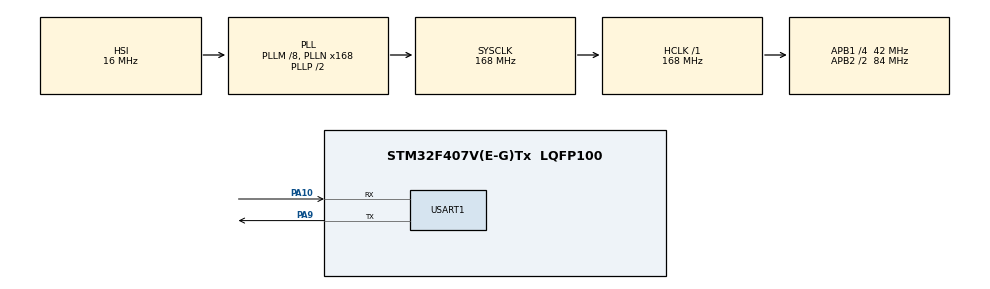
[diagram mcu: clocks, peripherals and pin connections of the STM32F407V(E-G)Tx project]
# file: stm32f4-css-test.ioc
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Mcu.Family=STM32F4
PH0-OSC_IN.Signal=RCC_OSC_IN
RCC.CortexFreq_Value=168000000
PA10.Mode=Asynchronous
RCC.APB1CLKDivider=RCC_HCLK_DIV4
RCC.SYSCLKSource=RCC_SYSCLKSOURCE_PLLCLK
ProjectManager.StackSize=0x400
PA13.Signal=SYS_JTMS-SWDIO
PA9.Mode=Asynchronous
ProjectManager.TargetToolchain=STM32CubeIDE
RCC.HCLKFreq_Value=168000000
RCC.APB2TimFreq_Value=168000000
PA9.Signal=USART1_TX
RCC.LSE_VALUE=32768
RCC.AHBFreq_Value=168000000
PH0-OSC_IN.Mode=HSE-External-Oscillator
RCC.HSE_VALUE=8000000
board=custom
RCC.VCOOutputFreq_Value=336000000
RCC.APB2Freq_Value=84000000
PA14.Mode=Serial_Wire
PH1-OSC_OUT.Signal=RCC_OSC_OUT
PA13.Mode=Serial_Wire
Mcu.Name=STM32F407V(E-G)Tx
PH1-OSC_OUT.Mode=HSE-External-Oscillator
RCC.48MHZClocksFreq_Value=84000000
RCC.SYSCLKFreq_VALUE=168000000
Mcu.Package=LQFP100
USART1.VirtualMode=VM_ASYNC
PA10.Signal=USART1_RX
PA14.Signal=SYS_JTCK-SWCLK
ProjectManager.HeapSize=0x200
RCC.HSI_VALUE=16000000
NVIC.PriorityGroup=NVIC_PRIORITYGROUP_4
RCC.APB2CLKDivider=RCC_HCLK_DIV2
RCC.PLLM=8
RCC.PLLN=168
RCC.APB1TimFreq_Value=84000000
RCC.APB1Freq_Value=42000000

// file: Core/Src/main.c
/* USER CODE BEGIN Header */
/**
  ******************************************************************************
  * @file           : main.c
  * @brief          : Main program body
  ******************************************************************************
  * @attention
  *
  * <h2><center>&copy; Copyright (c) 2021 STMicroelectronics.
  * All rights reserved.</center></h2>
  *
  * This software component is licensed by ST under BSD 3-Clause license,
  * the "License"; You may not use this file except in compliance with the
  * License. You may obtain a copy of the License at:
  *                        opensource.org/licenses/BSD-3-Clause
  *
  ******************************************************************************
  */
/* USER CODE END Header */
#include "main.h"

UART_HandleTypeDef huart1;

void SystemClock_Config(void);
static void MX_GPIO_Init(void);
static void MX_USART1_UART_Init(void);
/* USER CODE BEGIN PFP */
int clock_control__high_clocks_startup(void);
int app_main(void);
/* USER CODE END PFP */

int main(void)
{

  /* MCU Configuration--------------------------------------------------------*/

  /* Reset of all peripherals, Initializes the Flash interface and the Systick. */
  HAL_Init();

  /* USER CODE BEGIN Init */
#if 0
  /* USER CODE END Init */

  /* Configure the system clock */
  SystemClock_Config();

  /* USER CODE BEGIN SysInit */
#endif
  clock_control__high_clocks_startup();
  /* USER CODE END SysInit */

  /* Initialize all configured peripherals */
  MX_GPIO_Init();
  MX_USART1_UART_Init();
  /* USER CODE BEGIN 2 */
  app_main();
  /* USER CODE END 2 */

  /* Infinite loop */
  /* USER CODE BEGIN WHILE */
  while (1)
  {
    break;
    /* USER CODE END WHILE */

  }
}

void SystemClock_Config(void)
{
  RCC_OscInitTypeDef RCC_OscInitStruct = {0};
  RCC_ClkInitTypeDef RCC_ClkInitStruct = {0};

  /** Configure the main internal regulator output voltage
  */
  __HAL_RCC_PWR_CLK_ENABLE();
  __HAL_PWR_VOLTAGESCALING_CONFIG(PWR_REGULATOR_VOLTAGE_SCALE1);
  /** Initializes the RCC Oscillators according to the specified parameters
  * in the RCC_OscInitTypeDef structure.
  */
  RCC_OscInitStruct.OscillatorType = RCC_OSCILLATORTYPE_HSI;
  RCC_OscInitStruct.HSIState = RCC_HSI_ON;
  RCC_OscInitStruct.HSICalibrationValue = RCC_HSICALIBRATION_DEFAULT;
  RCC_OscInitStruct.PLL.PLLState = RCC_PLL_ON;
  RCC_OscInitStruct.PLL.PLLSource = RCC_PLLSOURCE_HSI;
  RCC_OscInitStruct.PLL.PLLM = 8;
  RCC_OscInitStruct.PLL.PLLN = 168;
  RCC_OscInitStruct.PLL.PLLP = RCC_PLLP_DIV2;
  RCC_OscInitStruct.PLL.PLLQ = 4;
  if (HAL_RCC_OscConfig(&RCC_OscInitStruct) != HAL_OK)
  {
    Error_Handler();
  }
  /** Initializes the CPU, AHB and APB buses clocks
  */
  RCC_ClkInitStruct.ClockType = RCC_CLOCKTYPE_HCLK|RCC_CLOCKTYPE_SYSCLK
                              |RCC_CLOCKTYPE_PCLK1|RCC_CLOCKTYPE_PCLK2;
  RCC_ClkInitStruct.SYSCLKSource = RCC_SYSCLKSOURCE_PLLCLK;
  RCC_ClkInitStruct.AHBCLKDivider = RCC_SYSCLK_DIV1;
  RCC_ClkInitStruct.APB1CLKDivider = RCC_HCLK_DIV4;
  RCC_ClkInitStruct.APB2CLKDivider = RCC_HCLK_DIV2;

  if (HAL_RCC_ClockConfig(&RCC_ClkInitStruct, FLASH_LATENCY_5) != HAL_OK)
  {
    Error_Handler();
  }
}

static void MX_USART1_UART_Init(void)
{

  huart1.Instance = USART1;
  huart1.Init.BaudRate = 115200;
  huart1.Init.WordLength = UART_WORDLENGTH_8B;
  huart1.Init.StopBits = UART_STOPBITS_1;
  huart1.Init.Parity = UART_PARITY_NONE;
  huart1.Init.Mode = UART_MODE_TX_RX;
  huart1.Init.HwFlowCtl = UART_HWCONTROL_NONE;
  huart1.Init.OverSampling = UART_OVERSAMPLING_16;
  if (HAL_UART_Init(&huart1) != HAL_OK)
  {
    Error_Handler();
  }

}

static void MX_GPIO_Init(void)
{

  /* GPIO Ports Clock Enable */
  __HAL_RCC_GPIOH_CLK_ENABLE();
  __HAL_RCC_GPIOA_CLK_ENABLE();

}

void Error_Handler(void)
{
  __disable_irq();
  while (1)
  {
  }
}

/************************ (C) COPYRIGHT STMicroelectronics *****END OF FILE****/
